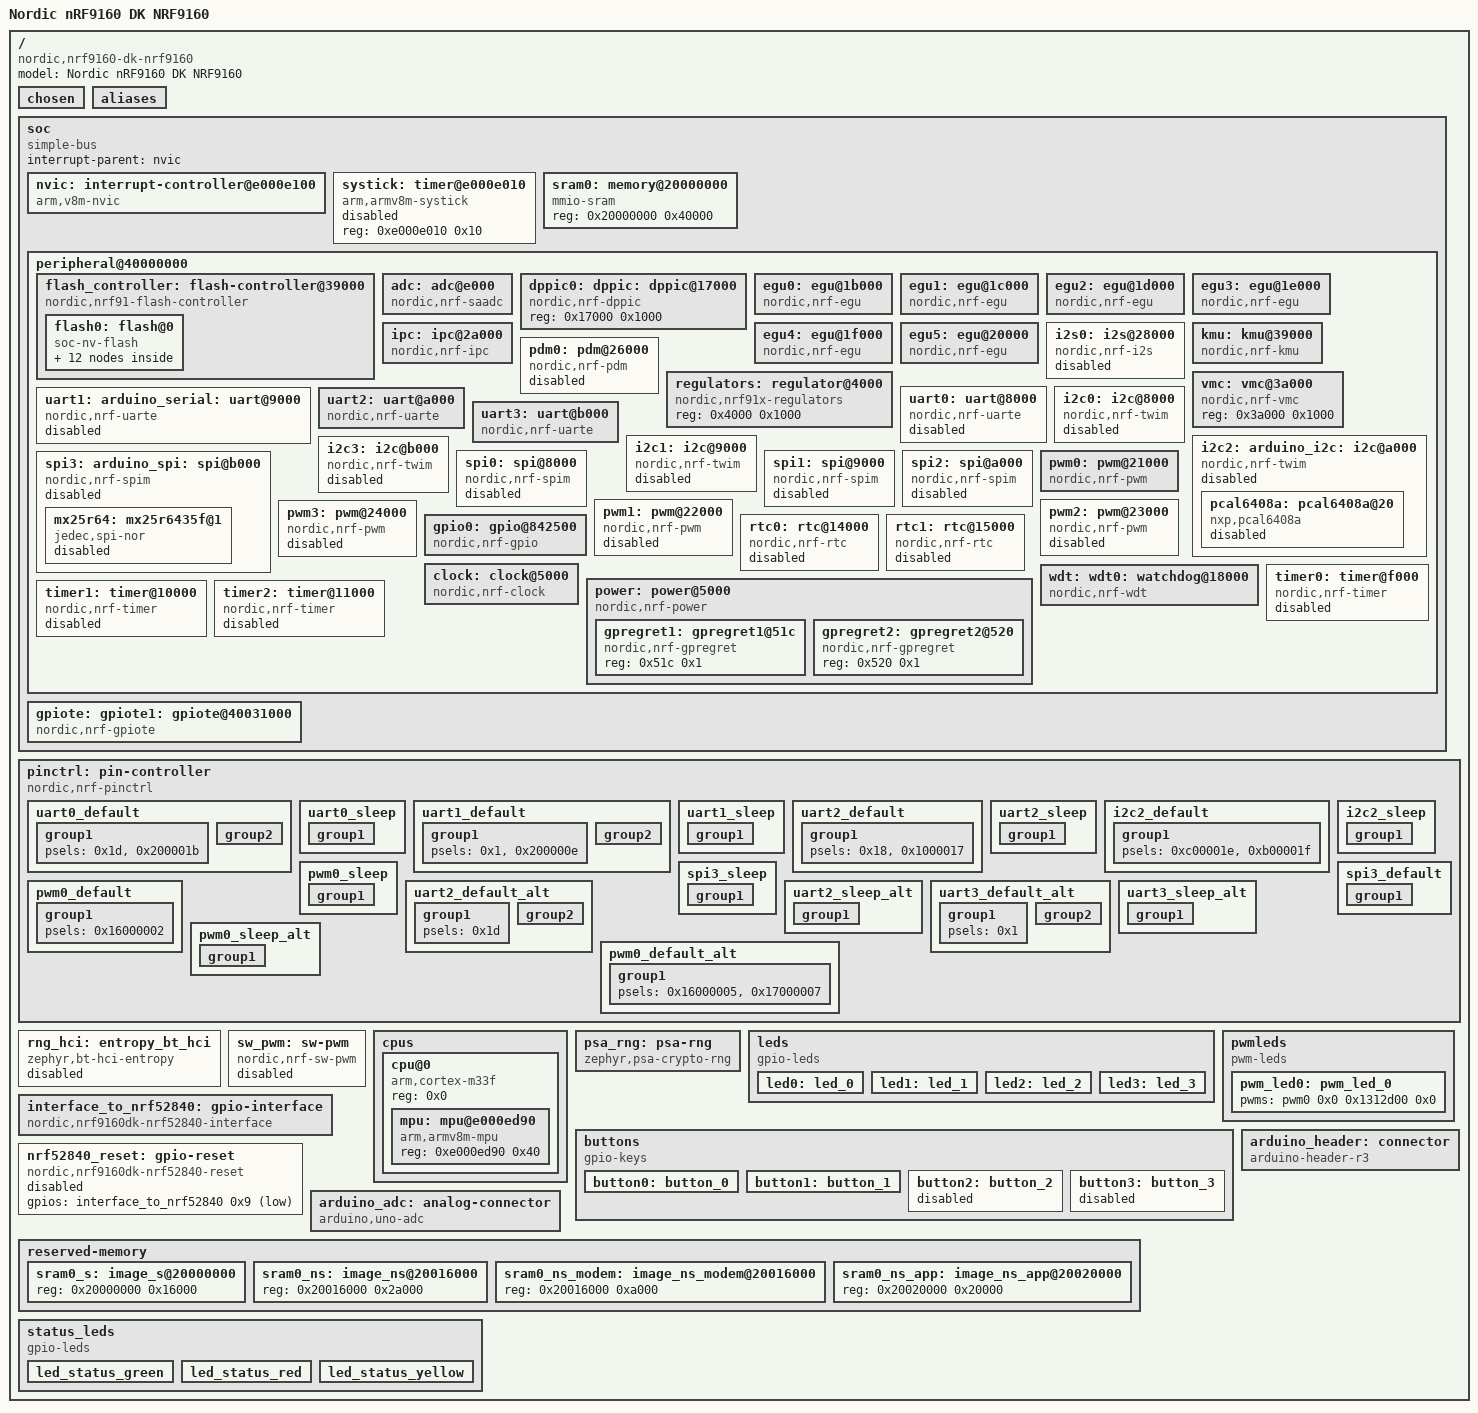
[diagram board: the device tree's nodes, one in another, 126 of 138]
/dts-v1/;

/* node '/' defined in zephyr\dts\common\skeleton.dtsi:9 */
/ {
	#address-cells = < 0x1 >;                 /* in zephyr\dts\common\skeleton.dtsi:10 */
	#size-cells = < 0x1 >;                    /* in zephyr\dts\common\skeleton.dtsi:11 */
	model = "Nordic nRF9160 DK NRF9160";      /* in zephyr\boards\nordic\nrf9160dk\nrf9160dk_nrf9160_common.dtsi:11 */
	compatible = "nordic,nrf9160-dk-nrf9160"; /* in zephyr\boards\nordic\nrf9160dk\nrf9160dk_nrf9160_common.dtsi:12 */

	/* node '/chosen' defined in zephyr\dts\common\skeleton.dtsi:12 */
	chosen {
		zephyr,entropy = &psa_rng;                   /* in zephyr\dts\arm\nordic\nrf91ns.dtsi:31 */
		zephyr,flash-controller = &flash_controller; /* in zephyr\dts\arm\nordic\nrf91ns.dtsi:32 */
		zephyr,console = &uart0;                     /* in zephyr\boards\nordic\nrf9160dk\nrf9160dk_nrf9160_common.dtsi:15 */
		zephyr,shell-uart = &uart0;                  /* in zephyr\boards\nordic\nrf9160dk\nrf9160dk_nrf9160_common.dtsi:16 */
		zephyr,uart-mcumgr = &uart0;                 /* in zephyr\boards\nordic\nrf9160dk\nrf9160dk_nrf9160_common.dtsi:17 */
		zephyr,flash = &flash0;                      /* in zephyr\boards\nordic\nrf9160dk\nrf9160dk_nrf9160_ns.dts:13 */
		zephyr,sram = &sram0_ns_app;                 /* in zephyr\boards\nordic\nrf9160dk\nrf9160dk_nrf9160_ns.dts:14 */
		zephyr,code-partition = &slot0_ns_partition; /* in zephyr\boards\nordic\nrf9160dk\nrf9160dk_nrf9160_ns.dts:15 */
	};

	/* node '/aliases' defined in zephyr\dts\common\skeleton.dtsi:13 */
	aliases {
		led0 = &led0;                           /* in zephyr\boards\nordic\nrf9160dk\nrf9160dk_nrf9160_common.dtsi:155 */
		led1 = &led1;                           /* in zephyr\boards\nordic\nrf9160dk\nrf9160dk_nrf9160_common.dtsi:156 */
		led2 = &led2;                           /* in zephyr\boards\nordic\nrf9160dk\nrf9160dk_nrf9160_common.dtsi:157 */
		led3 = &led3;                           /* in zephyr\boards\nordic\nrf9160dk\nrf9160dk_nrf9160_common.dtsi:158 */
		pwm-led0 = &pwm_led0;                   /* in zephyr\boards\nordic\nrf9160dk\nrf9160dk_nrf9160_common.dtsi:159 */
		sw0 = &button0;                         /* in zephyr\boards\nordic\nrf9160dk\nrf9160dk_nrf9160_common.dtsi:160 */
		sw1 = &button1;                         /* in zephyr\boards\nordic\nrf9160dk\nrf9160dk_nrf9160_common.dtsi:161 */
		sw2 = &button2;                         /* in zephyr\boards\nordic\nrf9160dk\nrf9160dk_nrf9160_common.dtsi:162 */
		sw3 = &button3;                         /* in zephyr\boards\nordic\nrf9160dk\nrf9160dk_nrf9160_common.dtsi:163 */
		mcuboot-button0 = &button0;             /* in zephyr\boards\nordic\nrf9160dk\nrf9160dk_nrf9160_common.dtsi:164 */
		mcuboot-led0 = &led0;                   /* in zephyr\boards\nordic\nrf9160dk\nrf9160dk_nrf9160_common.dtsi:165 */
		watchdog0 = &wdt0;                      /* in zephyr\boards\nordic\nrf9160dk\nrf9160dk_nrf9160_common.dtsi:166 */
		gps-uart = &uart2;                      /* in ..\firmware_dev\app.overlay:25 */
		esp-uart = &uart3;                      /* in ..\firmware_dev\app.overlay:26 */
		status-led = &led0;                     /* in ..\firmware_dev\app.overlay:28 */
		status-led-green = &led_status_green;   /* in ..\firmware_dev\app.overlay:30 */
		status-led-red = &led_status_red;       /* in ..\firmware_dev\app.overlay:31 */
		status-led-yellow = &led_status_yellow; /* in ..\firmware_dev\app.overlay:32 */
	};

	/* node '/soc' defined in zephyr\dts\arm\armv8-m.dtsi:6 */
	soc {
		#address-cells = < 0x1 >;     /* in zephyr\dts\arm\armv8-m.dtsi:7 */
		#size-cells = < 0x1 >;        /* in zephyr\dts\arm\armv8-m.dtsi:8 */
		interrupt-parent = < &nvic >; /* in zephyr\dts\arm\armv8-m.dtsi:10 */
		ranges;                       /* in zephyr\dts\arm\armv8-m.dtsi:11 */
		compatible = "simple-bus";    /* in zephyr\dts\arm\nordic\nrf9160ns_sica.dtsi:20 */

		/* node '/soc/interrupt-controller@e000e100' defined in zephyr\dts\arm\armv8-m.dtsi:13 */
		nvic: interrupt-controller@e000e100 {
			#address-cells = < 0x1 >;            /* in zephyr\dts\arm\armv8-m.dtsi:14 */
			compatible = "arm,v8m-nvic";         /* in zephyr\dts\arm\armv8-m.dtsi:15 */
			reg = < 0xe000e100 0xc00 >;          /* in zephyr\dts\arm\armv8-m.dtsi:16 */
			interrupt-controller;                /* in zephyr\dts\arm\armv8-m.dtsi:17 */
			#interrupt-cells = < 0x2 >;          /* in zephyr\dts\arm\armv8-m.dtsi:18 */
			arm,num-irq-priority-bits = < 0x3 >; /* in zephyr\dts\arm\nordic\nrf91ns.dtsi:70 */
			phandle = < 0x1 >;                   /* in zephyr\dts\arm\armv8-m.dtsi:10 */
		};

		/* node '/soc/timer@e000e010' defined in zephyr\dts\arm\armv8-m.dtsi:21 */
		systick: timer@e000e010 {
			compatible = "arm,armv8m-systick"; /* in zephyr\dts\arm\armv8-m.dtsi:22 */
			reg = < 0xe000e010 0x10 >;         /* in zephyr\dts\arm\armv8-m.dtsi:23 */
			status = "disabled";               /* in zephyr\dts\arm\nordic\nrf91ns.dtsi:75 */
		};

		/* node '/soc/memory@20000000' defined in zephyr\dts\arm\nordic\nrf91ns.dtsi:36 */
		sram0: memory@20000000 {
			compatible = "mmio-sram";     /* in zephyr\dts\arm\nordic\nrf91ns.dtsi:37 */
			reg = < 0x20000000 0x40000 >; /* in zephyr\dts\arm\nordic\nrf9160ns_sica.dtsi:15 */
		};

		/* node '/soc/peripheral@40000000' defined in zephyr\dts\arm\nordic\nrf91ns.dtsi:40 */
		peripheral@40000000 {
			#address-cells = < 0x1 >;               /* in zephyr\dts\arm\nordic\nrf91ns.dtsi:41 */
			#size-cells = < 0x1 >;                  /* in zephyr\dts\arm\nordic\nrf91ns.dtsi:42 */
			ranges = < 0x0 0x40000000 0x10000000 >; /* in zephyr\dts\arm\nordic\nrf91ns.dtsi:43 */

			/* node '/soc/peripheral@40000000/flash-controller@39000' defined in zephyr\dts\arm\nordic\nrf91_peripherals.dtsi:7 */
			flash_controller: flash-controller@39000 {
				compatible = "nordic,nrf91-flash-controller"; /* in zephyr\dts\arm\nordic\nrf91_peripherals.dtsi:8 */
				reg = < 0x39000 0x1000 >;                     /* in zephyr\dts\arm\nordic\nrf91_peripherals.dtsi:9 */
				partial-erase;                                /* in zephyr\dts\arm\nordic\nrf91_peripherals.dtsi:10 */
				#address-cells = < 0x1 >;                     /* in zephyr\dts\arm\nordic\nrf91_peripherals.dtsi:12 */
				#size-cells = < 0x1 >;                        /* in zephyr\dts\arm\nordic\nrf91_peripherals.dtsi:13 */

				/* node '/soc/peripheral@40000000/flash-controller@39000/flash@0' defined in zephyr\dts\arm\nordic\nrf91_peripherals.dtsi:15 */
				flash0: flash@0 {
					compatible = "soc-nv-flash";   /* in zephyr\dts\arm\nordic\nrf91_peripherals.dtsi:16 */
					erase-block-size = < 0x1000 >; /* in zephyr\dts\arm\nordic\nrf91_peripherals.dtsi:17 */
					write-block-size = < 0x4 >;    /* in zephyr\dts\arm\nordic\nrf91_peripherals.dtsi:18 */
					reg = < 0x0 0x100000 >;        /* in zephyr\dts\arm\nordic\nrf9160ns_sica.dtsi:11 */

					/* node '/soc/peripheral@40000000/flash-controller@39000/flash@0/partitions' defined in zephyr\dts\vendor\nordic\nrf91xx_partition.dtsi:27 */
					partitions {
						compatible = "fixed-partitions"; /* in zephyr\dts\vendor\nordic\nrf91xx_partition.dtsi:28 */
						#address-cells = < 0x1 >;        /* in zephyr\dts\vendor\nordic\nrf91xx_partition.dtsi:29 */
						#size-cells = < 0x1 >;           /* in zephyr\dts\vendor\nordic\nrf91xx_partition.dtsi:30 */

						/* node '/soc/peripheral@40000000/flash-controller@39000/flash@0/partitions/partition@0' defined in zephyr\dts\vendor\nordic\nrf91xx_partition.dtsi:32 */
						boot_partition: partition@0 {
							label = "mcuboot";     /* in zephyr\dts\vendor\nordic\nrf91xx_partition.dtsi:33 */
							reg = < 0x0 0x10000 >; /* in zephyr\dts\vendor\nordic\nrf91xx_partition.dtsi:34 */
						};

						/* node '/soc/peripheral@40000000/flash-controller@39000/flash@0/partitions/partition@10000' defined in zephyr\dts\vendor\nordic\nrf91xx_partition.dtsi:37 */
						slot0_partition: partition@10000 {
							compatible = "fixed-subpartitions"; /* in zephyr\dts\vendor\nordic\nrf91xx_partition.dtsi:38 */
							label = "image-0";                  /* in zephyr\dts\vendor\nordic\nrf91xx_partition.dtsi:39 */
							reg = < 0x10000 0x70000 >;          /* in zephyr\dts\vendor\nordic\nrf91xx_partition.dtsi:40 */
							ranges = < 0x0 0x10000 0x70000 >;   /* in zephyr\dts\vendor\nordic\nrf91xx_partition.dtsi:41 */
							#address-cells = < 0x1 >;           /* in zephyr\dts\vendor\nordic\nrf91xx_partition.dtsi:42 */
							#size-cells = < 0x1 >;              /* in zephyr\dts\vendor\nordic\nrf91xx_partition.dtsi:43 */

							/* node '/soc/peripheral@40000000/flash-controller@39000/flash@0/partitions/partition@10000/partition@0' defined in zephyr\dts\vendor\nordic\nrf91xx_partition.dtsi:45 */
							slot0_s_partition: partition@0 {
								label = "image-0-secure"; /* in zephyr\dts\vendor\nordic\nrf91xx_partition.dtsi:46 */
								reg = < 0x0 0x40000 >;    /* in zephyr\dts\vendor\nordic\nrf91xx_partition.dtsi:47 */
							};

							/* node '/soc/peripheral@40000000/flash-controller@39000/flash@0/partitions/partition@10000/partition@40000' defined in zephyr\dts\vendor\nordic\nrf91xx_partition.dtsi:50 */
							slot0_ns_partition: partition@40000 {
								label = "image-0-nonsecure"; /* in zephyr\dts\vendor\nordic\nrf91xx_partition.dtsi:51 */
								reg = < 0x40000 0x30000 >;   /* in zephyr\dts\vendor\nordic\nrf91xx_partition.dtsi:52 */
							};
						};

						/* node '/soc/peripheral@40000000/flash-controller@39000/flash@0/partitions/partition@80000' defined in zephyr\dts\vendor\nordic\nrf91xx_partition.dtsi:56 */
						slot1_partition: partition@80000 {
							compatible = "fixed-subpartitions"; /* in zephyr\dts\vendor\nordic\nrf91xx_partition.dtsi:57 */
							label = "image-1";                  /* in zephyr\dts\vendor\nordic\nrf91xx_partition.dtsi:58 */
							reg = < 0x80000 0x70000 >;          /* in zephyr\dts\vendor\nordic\nrf91xx_partition.dtsi:59 */
							ranges = < 0x0 0x80000 0x70000 >;   /* in zephyr\dts\vendor\nordic\nrf91xx_partition.dtsi:60 */
							#address-cells = < 0x1 >;           /* in zephyr\dts\vendor\nordic\nrf91xx_partition.dtsi:61 */
							#size-cells = < 0x1 >;              /* in zephyr\dts\vendor\nordic\nrf91xx_partition.dtsi:62 */

							/* node '/soc/peripheral@40000000/flash-controller@39000/flash@0/partitions/partition@80000/partition@0' defined in zephyr\dts\vendor\nordic\nrf91xx_partition.dtsi:64 */
							slot1_s_partition: partition@0 {
								label = "image-1-secure"; /* in zephyr\dts\vendor\nordic\nrf91xx_partition.dtsi:65 */
								reg = < 0x0 0x40000 >;    /* in zephyr\dts\vendor\nordic\nrf91xx_partition.dtsi:66 */
							};

							/* node '/soc/peripheral@40000000/flash-controller@39000/flash@0/partitions/partition@80000/partition@40000' defined in zephyr\dts\vendor\nordic\nrf91xx_partition.dtsi:69 */
							slot1_ns_partition: partition@40000 {
								label = "image-1-nonsecure"; /* in zephyr\dts\vendor\nordic\nrf91xx_partition.dtsi:70 */
								reg = < 0x40000 0x30000 >;   /* in zephyr\dts\vendor\nordic\nrf91xx_partition.dtsi:71 */
							};
						};

						/* node '/soc/peripheral@40000000/flash-controller@39000/flash@0/partitions/partition@f0000' defined in zephyr\dts\vendor\nordic\nrf91xx_partition.dtsi:75 */
						tfm_ps_partition: partition@f0000 {
							label = "tfm-ps";         /* in zephyr\dts\vendor\nordic\nrf91xx_partition.dtsi:76 */
							reg = < 0xf0000 0x4000 >; /* in zephyr\dts\vendor\nordic\nrf91xx_partition.dtsi:77 */
						};

						/* node '/soc/peripheral@40000000/flash-controller@39000/flash@0/partitions/partition@f4000' defined in zephyr\dts\vendor\nordic\nrf91xx_partition.dtsi:80 */
						tfm_its_partition: partition@f4000 {
							label = "tfm-its";        /* in zephyr\dts\vendor\nordic\nrf91xx_partition.dtsi:81 */
							reg = < 0xf4000 0x2000 >; /* in zephyr\dts\vendor\nordic\nrf91xx_partition.dtsi:82 */
						};

						/* node '/soc/peripheral@40000000/flash-controller@39000/flash@0/partitions/partition@f6000' defined in zephyr\dts\vendor\nordic\nrf91xx_partition.dtsi:85 */
						tfm_otp_partition: partition@f6000 {
							label = "tfm-otp";        /* in zephyr\dts\vendor\nordic\nrf91xx_partition.dtsi:86 */
							reg = < 0xf6000 0x2000 >; /* in zephyr\dts\vendor\nordic\nrf91xx_partition.dtsi:87 */
						};

						/* node '/soc/peripheral@40000000/flash-controller@39000/flash@0/partitions/partition@f8000' defined in zephyr\dts\vendor\nordic\nrf91xx_partition.dtsi:90 */
						storage_partition: partition@f8000 {
							label = "storage";        /* in zephyr\dts\vendor\nordic\nrf91xx_partition.dtsi:91 */
							reg = < 0xf8000 0x8000 >; /* in zephyr\dts\vendor\nordic\nrf91xx_partition.dtsi:92 */
						};
					};
				};
			};

			/* node '/soc/peripheral@40000000/adc@e000' defined in zephyr\dts\arm\nordic\nrf91_peripherals.dtsi:22 */
			adc: adc@e000 {
				compatible = "nordic,nrf-saadc"; /* in zephyr\dts\arm\nordic\nrf91_peripherals.dtsi:23 */
				reg = < 0xe000 0x1000 >;         /* in zephyr\dts\arm\nordic\nrf91_peripherals.dtsi:24 */
				interrupts = < 0xe 0x1 >;        /* in zephyr\dts\arm\nordic\nrf91_peripherals.dtsi:25 */
				#io-channel-cells = < 0x1 >;     /* in zephyr\dts\arm\nordic\nrf91_peripherals.dtsi:27 */
				zephyr,pm-device-runtime-auto;   /* in zephyr\dts\arm\nordic\nrf91_peripherals.dtsi:28 */
				status = "okay";                 /* in zephyr\boards\nordic\nrf9160dk\nrf9160dk_nrf9160_common.dtsi:171 */
				phandle = < 0x16 >;              /* in zephyr\boards\nordic\nrf9160dk\nrf9160dk_nrf9160_common.dtsi:145 */
			};

			/* node '/soc/peripheral@40000000/dppic@17000' defined in zephyr\dts\arm\nordic\nrf91_peripherals.dtsi:31 */
			dppic0: dppic: dppic@17000 {
				compatible = "nordic,nrf-dppic"; /* in zephyr\dts\arm\nordic\nrf91_peripherals.dtsi:32 */
				reg = < 0x17000 0x1000 >;        /* in zephyr\dts\arm\nordic\nrf91_peripherals.dtsi:33 */
				status = "okay";                 /* in zephyr\dts\arm\nordic\nrf91_peripherals.dtsi:34 */
			};

			/* node '/soc/peripheral@40000000/egu@1b000' defined in zephyr\dts\arm\nordic\nrf91_peripherals.dtsi:37 */
			egu0: egu@1b000 {
				compatible = "nordic,nrf-egu"; /* in zephyr\dts\arm\nordic\nrf91_peripherals.dtsi:38 */
				reg = < 0x1b000 0x1000 >;      /* in zephyr\dts\arm\nordic\nrf91_peripherals.dtsi:39 */
				interrupts = < 0x1b 0x1 >;     /* in zephyr\dts\arm\nordic\nrf91_peripherals.dtsi:40 */
				status = "okay";               /* in zephyr\dts\arm\nordic\nrf91_peripherals.dtsi:41 */
			};

			/* node '/soc/peripheral@40000000/egu@1c000' defined in zephyr\dts\arm\nordic\nrf91_peripherals.dtsi:44 */
			egu1: egu@1c000 {
				compatible = "nordic,nrf-egu"; /* in zephyr\dts\arm\nordic\nrf91_peripherals.dtsi:45 */
				reg = < 0x1c000 0x1000 >;      /* in zephyr\dts\arm\nordic\nrf91_peripherals.dtsi:46 */
				interrupts = < 0x1c 0x1 >;     /* in zephyr\dts\arm\nordic\nrf91_peripherals.dtsi:47 */
				status = "okay";               /* in zephyr\dts\arm\nordic\nrf91_peripherals.dtsi:48 */
			};

			/* node '/soc/peripheral@40000000/egu@1d000' defined in zephyr\dts\arm\nordic\nrf91_peripherals.dtsi:51 */
			egu2: egu@1d000 {
				compatible = "nordic,nrf-egu"; /* in zephyr\dts\arm\nordic\nrf91_peripherals.dtsi:52 */
				reg = < 0x1d000 0x1000 >;      /* in zephyr\dts\arm\nordic\nrf91_peripherals.dtsi:53 */
				interrupts = < 0x1d 0x1 >;     /* in zephyr\dts\arm\nordic\nrf91_peripherals.dtsi:54 */
				status = "okay";               /* in zephyr\dts\arm\nordic\nrf91_peripherals.dtsi:55 */
			};

			/* node '/soc/peripheral@40000000/egu@1e000' defined in zephyr\dts\arm\nordic\nrf91_peripherals.dtsi:58 */
			egu3: egu@1e000 {
				compatible = "nordic,nrf-egu"; /* in zephyr\dts\arm\nordic\nrf91_peripherals.dtsi:59 */
				reg = < 0x1e000 0x1000 >;      /* in zephyr\dts\arm\nordic\nrf91_peripherals.dtsi:60 */
				interrupts = < 0x1e 0x1 >;     /* in zephyr\dts\arm\nordic\nrf91_peripherals.dtsi:61 */
				status = "okay";               /* in zephyr\dts\arm\nordic\nrf91_peripherals.dtsi:62 */
			};

			/* node '/soc/peripheral@40000000/egu@1f000' defined in zephyr\dts\arm\nordic\nrf91_peripherals.dtsi:65 */
			egu4: egu@1f000 {
				compatible = "nordic,nrf-egu"; /* in zephyr\dts\arm\nordic\nrf91_peripherals.dtsi:66 */
				reg = < 0x1f000 0x1000 >;      /* in zephyr\dts\arm\nordic\nrf91_peripherals.dtsi:67 */
				interrupts = < 0x1f 0x1 >;     /* in zephyr\dts\arm\nordic\nrf91_peripherals.dtsi:68 */
				status = "okay";               /* in zephyr\dts\arm\nordic\nrf91_peripherals.dtsi:69 */
			};

			/* node '/soc/peripheral@40000000/egu@20000' defined in zephyr\dts\arm\nordic\nrf91_peripherals.dtsi:72 */
			egu5: egu@20000 {
				compatible = "nordic,nrf-egu"; /* in zephyr\dts\arm\nordic\nrf91_peripherals.dtsi:73 */
				reg = < 0x20000 0x1000 >;      /* in zephyr\dts\arm\nordic\nrf91_peripherals.dtsi:74 */
				interrupts = < 0x20 0x1 >;     /* in zephyr\dts\arm\nordic\nrf91_peripherals.dtsi:75 */
				status = "okay";               /* in zephyr\dts\arm\nordic\nrf91_peripherals.dtsi:76 */
			};

			/* node '/soc/peripheral@40000000/ipc@2a000' defined in zephyr\dts\arm\nordic\nrf91_peripherals.dtsi:79 */
			ipc: ipc@2a000 {
				compatible = "nordic,nrf-ipc"; /* in zephyr\dts\arm\nordic\nrf91_peripherals.dtsi:80 */
				reg = < 0x2a000 0x1000 >;      /* in zephyr\dts\arm\nordic\nrf91_peripherals.dtsi:81 */
				interrupts = < 0x2a 0x1 >;     /* in zephyr\dts\arm\nordic\nrf91_peripherals.dtsi:82 */
				status = "okay";               /* in zephyr\dts\arm\nordic\nrf91_peripherals.dtsi:83 */
			};

			/* node '/soc/peripheral@40000000/i2s@28000' defined in zephyr\dts\arm\nordic\nrf91_peripherals.dtsi:86 */
			i2s0: i2s@28000 {
				compatible = "nordic,nrf-i2s"; /* in zephyr\dts\arm\nordic\nrf91_peripherals.dtsi:87 */
				#address-cells = < 0x1 >;      /* in zephyr\dts\arm\nordic\nrf91_peripherals.dtsi:88 */
				#size-cells = < 0x0 >;         /* in zephyr\dts\arm\nordic\nrf91_peripherals.dtsi:89 */
				reg = < 0x28000 0x1000 >;      /* in zephyr\dts\arm\nordic\nrf91_peripherals.dtsi:90 */
				interrupts = < 0x28 0x1 >;     /* in zephyr\dts\arm\nordic\nrf91_peripherals.dtsi:91 */
				status = "disabled";           /* in zephyr\dts\arm\nordic\nrf91_peripherals.dtsi:92 */
			};

			/* node '/soc/peripheral@40000000/kmu@39000' defined in zephyr\dts\arm\nordic\nrf91_peripherals.dtsi:95 */
			kmu: kmu@39000 {
				compatible = "nordic,nrf-kmu"; /* in zephyr\dts\arm\nordic\nrf91_peripherals.dtsi:96 */
				reg = < 0x39000 0x1000 >;      /* in zephyr\dts\arm\nordic\nrf91_peripherals.dtsi:97 */
				interrupts = < 0x39 0x1 >;     /* in zephyr\dts\arm\nordic\nrf91_peripherals.dtsi:98 */
				status = "okay";               /* in zephyr\dts\arm\nordic\nrf91_peripherals.dtsi:99 */
			};

			/* node '/soc/peripheral@40000000/pdm@26000' defined in zephyr\dts\arm\nordic\nrf91_peripherals.dtsi:102 */
			pdm0: pdm@26000 {
				compatible = "nordic,nrf-pdm"; /* in zephyr\dts\arm\nordic\nrf91_peripherals.dtsi:103 */
				reg = < 0x26000 0x1000 >;      /* in zephyr\dts\arm\nordic\nrf91_peripherals.dtsi:104 */
				interrupts = < 0x26 0x1 >;     /* in zephyr\dts\arm\nordic\nrf91_peripherals.dtsi:105 */
				status = "disabled";           /* in zephyr\dts\arm\nordic\nrf91_peripherals.dtsi:106 */
			};

			/* node '/soc/peripheral@40000000/regulator@4000' defined in zephyr\dts\arm\nordic\nrf91_peripherals.dtsi:109 */
			regulators: regulator@4000 {
				compatible = "nordic,nrf91x-regulators"; /* in zephyr\dts\arm\nordic\nrf91_peripherals.dtsi:110 */
				reg = < 0x4000 0x1000 >;                 /* in zephyr\dts\arm\nordic\nrf91_peripherals.dtsi:111 */
				status = "okay";                         /* in zephyr\dts\arm\nordic\nrf91_peripherals.dtsi:112 */
			};

			/* node '/soc/peripheral@40000000/vmc@3a000' defined in zephyr\dts\arm\nordic\nrf91_peripherals.dtsi:115 */
			vmc: vmc@3a000 {
				compatible = "nordic,nrf-vmc"; /* in zephyr\dts\arm\nordic\nrf91_peripherals.dtsi:116 */
				reg = < 0x3a000 0x1000 >;      /* in zephyr\dts\arm\nordic\nrf91_peripherals.dtsi:117 */
				status = "okay";               /* in zephyr\dts\arm\nordic\nrf91_peripherals.dtsi:118 */
			};

			/* node '/soc/peripheral@40000000/uart@8000' defined in zephyr\dts\arm\nordic\nrf91_peripherals.dtsi:121 */
			uart0: uart@8000 {
				compatible = "nordic,nrf-uarte"; /* in zephyr\dts\arm\nordic\nrf91_peripherals.dtsi:122 */
				reg = < 0x8000 0x1000 >;         /* in zephyr\dts\arm\nordic\nrf91_peripherals.dtsi:123 */
				interrupts = < 0x8 0x1 >;        /* in zephyr\dts\arm\nordic\nrf91_peripherals.dtsi:124 */
				current-speed = < 0x1c200 >;     /* in zephyr\boards\nordic\nrf9160dk\nrf9160dk_nrf9160_common.dtsi:184 */
				pinctrl-0 = < &uart0_default >;  /* in zephyr\boards\nordic\nrf9160dk\nrf9160dk_nrf9160_common.dtsi:185 */
				pinctrl-1 = < &uart0_sleep >;    /* in zephyr\boards\nordic\nrf9160dk\nrf9160dk_nrf9160_common.dtsi:186 */
				pinctrl-names = "default",
				                "sleep";         /* in zephyr\boards\nordic\nrf9160dk\nrf9160dk_nrf9160_common.dtsi:187 */
				status = "disabled";             /* in ..\firmware_dev\app.overlay:133 */
			};

			/* node '/soc/peripheral@40000000/uart@9000' defined in zephyr\dts\arm\nordic\nrf91_peripherals.dtsi:128 */
			uart1: arduino_serial: uart@9000 {
				compatible = "nordic,nrf-uarte"; /* in zephyr\dts\arm\nordic\nrf91_peripherals.dtsi:129 */
				reg = < 0x9000 0x1000 >;         /* in zephyr\dts\arm\nordic\nrf91_peripherals.dtsi:130 */
				interrupts = < 0x9 0x1 >;        /* in zephyr\dts\arm\nordic\nrf91_peripherals.dtsi:131 */
				current-speed = < 0x1c200 >;     /* in zephyr\boards\nordic\nrf9160dk\nrf9160dk_nrf9160_common.dtsi:192 */
				pinctrl-0 = < &uart1_default >;  /* in zephyr\boards\nordic\nrf9160dk\nrf9160dk_nrf9160_common.dtsi:193 */
				pinctrl-1 = < &uart1_sleep >;    /* in zephyr\boards\nordic\nrf9160dk\nrf9160dk_nrf9160_common.dtsi:194 */
				pinctrl-names = "default",
				                "sleep";         /* in zephyr\boards\nordic\nrf9160dk\nrf9160dk_nrf9160_common.dtsi:195 */
				status = "disabled";             /* in zephyr\boards\nordic\nrf9160dk\nrf9160dk_nrf9160_ns.dts:21 */
			};

			/* node '/soc/peripheral@40000000/uart@a000' defined in zephyr\dts\arm\nordic\nrf91_peripherals.dtsi:135 */
			uart2: uart@a000 {
				compatible = "nordic,nrf-uarte";    /* in zephyr\dts\arm\nordic\nrf91_peripherals.dtsi:136 */
				reg = < 0xa000 0x1000 >;            /* in zephyr\dts\arm\nordic\nrf91_peripherals.dtsi:137 */
				interrupts = < 0xa 0x1 >;           /* in zephyr\dts\arm\nordic\nrf91_peripherals.dtsi:138 */
				status = "okay";                    /* in ..\firmware_dev\app.overlay:163 */
				current-speed = < 0x9600 >;         /* in ..\firmware_dev\app.overlay:164 */
				pinctrl-0 = < &uart2_default_alt >; /* in ..\firmware_dev\app.overlay:165 */
				pinctrl-1 = < &uart2_sleep_alt >;   /* in ..\firmware_dev\app.overlay:166 */
				pinctrl-names = "default",
				                "sleep";            /* in ..\firmware_dev\app.overlay:167 */
			};

			/* node '/soc/peripheral@40000000/uart@b000' defined in zephyr\dts\arm\nordic\nrf91_peripherals.dtsi:142 */
			uart3: uart@b000 {
				compatible = "nordic,nrf-uarte";    /* in zephyr\dts\arm\nordic\nrf91_peripherals.dtsi:143 */
				reg = < 0xb000 0x1000 >;            /* in zephyr\dts\arm\nordic\nrf91_peripherals.dtsi:144 */
				interrupts = < 0xb 0x1 >;           /* in zephyr\dts\arm\nordic\nrf91_peripherals.dtsi:145 */
				status = "okay";                    /* in ..\firmware_dev\app.overlay:147 */
				current-speed = < 0x1c200 >;        /* in ..\firmware_dev\app.overlay:148 */
				pinctrl-0 = < &uart3_default_alt >; /* in ..\firmware_dev\app.overlay:149 */
				pinctrl-1 = < &uart3_sleep_alt >;   /* in ..\firmware_dev\app.overlay:150 */
				pinctrl-names = "default",
				                "sleep";            /* in ..\firmware_dev\app.overlay:151 */
			};

			/* node '/soc/peripheral@40000000/i2c@8000' defined in zephyr\dts\arm\nordic\nrf91_peripherals.dtsi:149 */
			i2c0: i2c@8000 {
				compatible = "nordic,nrf-twim"; /* in zephyr\dts\arm\nordic\nrf91_peripherals.dtsi:155 */
				#address-cells = < 0x1 >;       /* in zephyr\dts\arm\nordic\nrf91_peripherals.dtsi:156 */
				#size-cells = < 0x0 >;          /* in zephyr\dts\arm\nordic\nrf91_peripherals.dtsi:157 */
				reg = < 0x8000 0x1000 >;        /* in zephyr\dts\arm\nordic\nrf91_peripherals.dtsi:158 */
				interrupts = < 0x8 0x1 >;       /* in zephyr\dts\arm\nordic\nrf91_peripherals.dtsi:159 */
				easydma-maxcnt-bits = < 0xd >;  /* in zephyr\dts\arm\nordic\nrf91_peripherals.dtsi:160 */
				status = "disabled";            /* in zephyr\dts\arm\nordic\nrf91_peripherals.dtsi:161 */
				zephyr,pm-device-runtime-auto;  /* in zephyr\dts\arm\nordic\nrf91_peripherals.dtsi:162 */
			};

			/* node '/soc/peripheral@40000000/i2c@9000' defined in zephyr\dts\arm\nordic\nrf91_peripherals.dtsi:165 */
			i2c1: i2c@9000 {
				compatible = "nordic,nrf-twim"; /* in zephyr\dts\arm\nordic\nrf91_peripherals.dtsi:171 */
				#address-cells = < 0x1 >;       /* in zephyr\dts\arm\nordic\nrf91_peripherals.dtsi:172 */
				#size-cells = < 0x0 >;          /* in zephyr\dts\arm\nordic\nrf91_peripherals.dtsi:173 */
				reg = < 0x9000 0x1000 >;        /* in zephyr\dts\arm\nordic\nrf91_peripherals.dtsi:174 */
				interrupts = < 0x9 0x1 >;       /* in zephyr\dts\arm\nordic\nrf91_peripherals.dtsi:175 */
				easydma-maxcnt-bits = < 0xd >;  /* in zephyr\dts\arm\nordic\nrf91_peripherals.dtsi:176 */
				status = "disabled";            /* in zephyr\dts\arm\nordic\nrf91_peripherals.dtsi:177 */
				zephyr,pm-device-runtime-auto;  /* in zephyr\dts\arm\nordic\nrf91_peripherals.dtsi:178 */
			};

			/* node '/soc/peripheral@40000000/i2c@a000' defined in zephyr\dts\arm\nordic\nrf91_peripherals.dtsi:181 */
			i2c2: arduino_i2c: i2c@a000 {
				#address-cells = < 0x1 >;       /* in zephyr\dts\arm\nordic\nrf91_peripherals.dtsi:188 */
				#size-cells = < 0x0 >;          /* in zephyr\dts\arm\nordic\nrf91_peripherals.dtsi:189 */
				reg = < 0xa000 0x1000 >;        /* in zephyr\dts\arm\nordic\nrf91_peripherals.dtsi:190 */
				interrupts = < 0xa 0x1 >;       /* in zephyr\dts\arm\nordic\nrf91_peripherals.dtsi:191 */
				easydma-maxcnt-bits = < 0xd >;  /* in zephyr\dts\arm\nordic\nrf91_peripherals.dtsi:192 */
				zephyr,pm-device-runtime-auto;  /* in zephyr\dts\arm\nordic\nrf91_peripherals.dtsi:194 */
				compatible = "nordic,nrf-twim"; /* in zephyr\boards\nordic\nrf9160dk\nrf9160dk_nrf9160_common.dtsi:205 */
				pinctrl-0 = < &i2c2_default >;  /* in zephyr\boards\nordic\nrf9160dk\nrf9160dk_nrf9160_common.dtsi:207 */
				pinctrl-1 = < &i2c2_sleep >;    /* in zephyr\boards\nordic\nrf9160dk\nrf9160dk_nrf9160_common.dtsi:208 */
				pinctrl-names = "default",
				                "sleep";        /* in zephyr\boards\nordic\nrf9160dk\nrf9160dk_nrf9160_common.dtsi:209 */
				clock-frequency = < 0x61a80 >;  /* in zephyr\boards\nordic\nrf9160dk\nrf9160dk_nrf9160_common_0_14_0.dtsi:26 */
				status = "disabled";            /* in ..\firmware_dev\app.overlay:138 */

				/* node '/soc/peripheral@40000000/i2c@a000/pcal6408a@20' defined in zephyr\boards\nordic\nrf9160dk\nrf9160dk_nrf9160_common_0_14_0.dtsi:28 */
				pcal6408a: pcal6408a@20 {
					compatible = "nxp,pcal6408a";    /* in zephyr\boards\nordic\nrf9160dk\nrf9160dk_nrf9160_common_0_14_0.dtsi:29 */
					status = "disabled";             /* in zephyr\boards\nordic\nrf9160dk\nrf9160dk_nrf9160_common_0_14_0.dtsi:30 */
					reg = < 0x20 >;                  /* in zephyr\boards\nordic\nrf9160dk\nrf9160dk_nrf9160_common_0_14_0.dtsi:31 */
					gpio-controller;                 /* in zephyr\boards\nordic\nrf9160dk\nrf9160dk_nrf9160_common_0_14_0.dtsi:32 */
					#gpio-cells = < 0x2 >;           /* in zephyr\boards\nordic\nrf9160dk\nrf9160dk_nrf9160_common_0_14_0.dtsi:33 */
					ngpios = < 0x8 >;                /* in zephyr\boards\nordic\nrf9160dk\nrf9160dk_nrf9160_common_0_14_0.dtsi:34 */
					int-gpios = < &gpio0 0x6 0x11 >; /* in zephyr\boards\nordic\nrf9160dk\nrf9160dk_nrf9160_common_0_14_0.dtsi:35 */
				};
			};

			/* node '/soc/peripheral@40000000/i2c@b000' defined in zephyr\dts\arm\nordic\nrf91_peripherals.dtsi:197 */
			i2c3: i2c@b000 {
				compatible = "nordic,nrf-twim"; /* in zephyr\dts\arm\nordic\nrf91_peripherals.dtsi:203 */
				#address-cells = < 0x1 >;       /* in zephyr\dts\arm\nordic\nrf91_peripherals.dtsi:204 */
				#size-cells = < 0x0 >;          /* in zephyr\dts\arm\nordic\nrf91_peripherals.dtsi:205 */
				reg = < 0xb000 0x1000 >;        /* in zephyr\dts\arm\nordic\nrf91_peripherals.dtsi:206 */
				interrupts = < 0xb 0x1 >;       /* in zephyr\dts\arm\nordic\nrf91_peripherals.dtsi:207 */
				easydma-maxcnt-bits = < 0xd >;  /* in zephyr\dts\arm\nordic\nrf91_peripherals.dtsi:208 */
				status = "disabled";            /* in zephyr\dts\arm\nordic\nrf91_peripherals.dtsi:209 */
				zephyr,pm-device-runtime-auto;  /* in zephyr\dts\arm\nordic\nrf91_peripherals.dtsi:210 */
			};

			/* node '/soc/peripheral@40000000/spi@8000' defined in zephyr\dts\arm\nordic\nrf91_peripherals.dtsi:213 */
			spi0: spi@8000 {
				compatible = "nordic,nrf-spim"; /* in zephyr\dts\arm\nordic\nrf91_peripherals.dtsi:219 */
				#address-cells = < 0x1 >;       /* in zephyr\dts\arm\nordic\nrf91_peripherals.dtsi:220 */
				#size-cells = < 0x0 >;          /* in zephyr\dts\arm\nordic\nrf91_peripherals.dtsi:221 */
				reg = < 0x8000 0x1000 >;        /* in zephyr\dts\arm\nordic\nrf91_peripherals.dtsi:222 */
				interrupts = < 0x8 0x1 >;       /* in zephyr\dts\arm\nordic\nrf91_peripherals.dtsi:223 */
				max-frequency = < 0x7a1200 >;   /* in zephyr\dts\arm\nordic\nrf91_peripherals.dtsi:224 */
				easydma-maxcnt-bits = < 0xd >;  /* in zephyr\dts\arm\nordic\nrf91_peripherals.dtsi:225 */
				status = "disabled";            /* in zephyr\dts\arm\nordic\nrf91_peripherals.dtsi:226 */
			};

			/* node '/soc/peripheral@40000000/spi@9000' defined in zephyr\dts\arm\nordic\nrf91_peripherals.dtsi:229 */
			spi1: spi@9000 {
				compatible = "nordic,nrf-spim"; /* in zephyr\dts\arm\nordic\nrf91_peripherals.dtsi:235 */
				#address-cells = < 0x1 >;       /* in zephyr\dts\arm\nordic\nrf91_peripherals.dtsi:236 */
				#size-cells = < 0x0 >;          /* in zephyr\dts\arm\nordic\nrf91_peripherals.dtsi:237 */
				reg = < 0x9000 0x1000 >;        /* in zephyr\dts\arm\nordic\nrf91_peripherals.dtsi:238 */
				interrupts = < 0x9 0x1 >;       /* in zephyr\dts\arm\nordic\nrf91_peripherals.dtsi:239 */
				max-frequency = < 0x7a1200 >;   /* in zephyr\dts\arm\nordic\nrf91_peripherals.dtsi:240 */
				easydma-maxcnt-bits = < 0xd >;  /* in zephyr\dts\arm\nordic\nrf91_peripherals.dtsi:241 */
				status = "disabled";            /* in zephyr\dts\arm\nordic\nrf91_peripherals.dtsi:242 */
			};

			/* node '/soc/peripheral@40000000/spi@a000' defined in zephyr\dts\arm\nordic\nrf91_peripherals.dtsi:245 */
			spi2: spi@a000 {
				compatible = "nordic,nrf-spim"; /* in zephyr\dts\arm\nordic\nrf91_peripherals.dtsi:251 */
				#address-cells = < 0x1 >;       /* in zephyr\dts\arm\nordic\nrf91_peripherals.dtsi:252 */
				#size-cells = < 0x0 >;          /* in zephyr\dts\arm\nordic\nrf91_peripherals.dtsi:253 */
				reg = < 0xa000 0x1000 >;        /* in zephyr\dts\arm\nordic\nrf91_peripherals.dtsi:254 */
				interrupts = < 0xa 0x1 >;       /* in zephyr\dts\arm\nordic\nrf91_peripherals.dtsi:255 */
				max-frequency = < 0x7a1200 >;   /* in zephyr\dts\arm\nordic\nrf91_peripherals.dtsi:256 */
				easydma-maxcnt-bits = < 0xd >;  /* in zephyr\dts\arm\nordic\nrf91_peripherals.dtsi:257 */
				status = "disabled";            /* in zephyr\dts\arm\nordic\nrf91_peripherals.dtsi:258 */
			};

			/* node '/soc/peripheral@40000000/spi@b000' defined in zephyr\dts\arm\nordic\nrf91_peripherals.dtsi:261 */
			spi3: arduino_spi: spi@b000 {
				#address-cells = < 0x1 >;                /* in zephyr\dts\arm\nordic\nrf91_peripherals.dtsi:268 */
				#size-cells = < 0x0 >;                   /* in zephyr\dts\arm\nordic\nrf91_peripherals.dtsi:269 */
				reg = < 0xb000 0x1000 >;                 /* in zephyr\dts\arm\nordic\nrf91_peripherals.dtsi:270 */
				interrupts = < 0xb 0x1 >;                /* in zephyr\dts\arm\nordic\nrf91_peripherals.dtsi:271 */
				max-frequency = < 0x7a1200 >;            /* in zephyr\dts\arm\nordic\nrf91_peripherals.dtsi:272 */
				easydma-maxcnt-bits = < 0xd >;           /* in zephyr\dts\arm\nordic\nrf91_peripherals.dtsi:273 */
				compatible = "nordic,nrf-spim";          /* in zephyr\boards\nordic\nrf9160dk\nrf9160dk_nrf9160_common.dtsi:220 */
				pinctrl-0 = < &spi3_default >;           /* in zephyr\boards\nordic\nrf9160dk\nrf9160dk_nrf9160_common.dtsi:223 */
				pinctrl-1 = < &spi3_sleep >;             /* in zephyr\boards\nordic\nrf9160dk\nrf9160dk_nrf9160_common.dtsi:224 */
				pinctrl-names = "default",
				                "sleep";                 /* in zephyr\boards\nordic\nrf9160dk\nrf9160dk_nrf9160_common.dtsi:225 */
				cs-gpios = < &arduino_header 0x10 0x1 >,
				           < &gpio0 0x19 0x1 >;          /* in zephyr\boards\nordic\nrf9160dk\nrf9160dk_nrf9160_common_0_14_0.dtsi:40 */
				status = "disabled";                     /* in ..\firmware_dev\app.overlay:143 */

				/* node '/soc/peripheral@40000000/spi@b000/mx25r6435f@1' defined in zephyr\boards\nordic\nrf9160dk\nrf9160dk_nrf9160_common_0_14_0.dtsi:43 */
				mx25r64: mx25r6435f@1 {
					compatible = "jedec,spi-nor";                                                                 /* in zephyr\boards\nordic\nrf9160dk\nrf9160dk_nrf9160_common_0_14_0.dtsi:44 */
					status = "disabled";                                                                          /* in zephyr\boards\nordic\nrf9160dk\nrf9160dk_nrf9160_common_0_14_0.dtsi:45 */
					reg = < 0x1 >;                                                                                /* in zephyr\boards\nordic\nrf9160dk\nrf9160dk_nrf9160_common_0_14_0.dtsi:46 */
					spi-max-frequency = < 0x7a1200 >;                                                             /* in zephyr\boards\nordic\nrf9160dk\nrf9160dk_nrf9160_common_0_14_0.dtsi:47 */
					jedec-id = [ C2 28 17 ];                                                                      /* in zephyr\boards\nordic\nrf9160dk\nrf9160dk_nrf9160_common_0_14_0.dtsi:48 */
					sfdp-bfp = [ E5 20 F1 FF FF FF FF 03 44 EB 08 6B 08 3B 04 BB EE FF FF FF FF FF 00 FF FF FF 00
					             FF 0C 20 0F 52 10 D8 00 FF 23 72 F5 00 82 ED 04 CC 44 83 48 44 30 B0 30 B0 F7 C4
					             D5 5C 00 BE 29 FF F0 D0 FF FF ];                                                 /* in zephyr\boards\nordic\nrf9160dk\nrf9160dk_nrf9160_common_0_14_0.dtsi:49 */
					size = < 0x4000000 >;                                                                         /* in zephyr\boards\nordic\nrf9160dk\nrf9160dk_nrf9160_common_0_14_0.dtsi:55 */
					has-dpd;                                                                                      /* in zephyr\boards\nordic\nrf9160dk\nrf9160dk_nrf9160_common_0_14_0.dtsi:56 */
					t-enter-dpd = < 0x2710 >;                                                                     /* in zephyr\boards\nordic\nrf9160dk\nrf9160dk_nrf9160_common_0_14_0.dtsi:57 */
					t-exit-dpd = < 0x88b8 >;                                                                      /* in zephyr\boards\nordic\nrf9160dk\nrf9160dk_nrf9160_common_0_14_0.dtsi:58 */
				};
			};

			/* node '/soc/peripheral@40000000/pwm@21000' defined in zephyr\dts\arm\nordic\nrf91_peripherals.dtsi:277 */
			pwm0: pwm@21000 {
				compatible = "nordic,nrf-pwm";     /* in zephyr\dts\arm\nordic\nrf91_peripherals.dtsi:278 */
				reg = < 0x21000 0x1000 >;          /* in zephyr\dts\arm\nordic\nrf91_peripherals.dtsi:279 */
				interrupts = < 0x21 0x1 >;         /* in zephyr\dts\arm\nordic\nrf91_peripherals.dtsi:280 */
				#pwm-cells = < 0x3 >;              /* in zephyr\dts\arm\nordic\nrf91_peripherals.dtsi:282 */
				status = "okay";                   /* in ..\firmware_dev\app.overlay:156 */
				pinctrl-0 = < &pwm0_default_alt >; /* in ..\firmware_dev\app.overlay:157 */
				pinctrl-1 = < &pwm0_sleep_alt >;   /* in ..\firmware_dev\app.overlay:158 */
				pinctrl-names = "default",
				                "sleep";           /* in ..\firmware_dev\app.overlay:159 */
				phandle = < 0x14 >;                /* in zephyr\boards\nordic\nrf9160dk\nrf9160dk_nrf9160_common.dtsi:48 */
			};

			/* node '/soc/peripheral@40000000/pwm@22000' defined in zephyr\dts\arm\nordic\nrf91_peripherals.dtsi:285 */
			pwm1: pwm@22000 {
				compatible = "nordic,nrf-pwm"; /* in zephyr\dts\arm\nordic\nrf91_peripherals.dtsi:286 */
				reg = < 0x22000 0x1000 >;      /* in zephyr\dts\arm\nordic\nrf91_peripherals.dtsi:287 */
				interrupts = < 0x22 0x1 >;     /* in zephyr\dts\arm\nordic\nrf91_peripherals.dtsi:288 */
				status = "disabled";           /* in zephyr\dts\arm\nordic\nrf91_peripherals.dtsi:289 */
				#pwm-cells = < 0x3 >;          /* in zephyr\dts\arm\nordic\nrf91_peripherals.dtsi:290 */
			};

			/* node '/soc/peripheral@40000000/pwm@23000' defined in zephyr\dts\arm\nordic\nrf91_peripherals.dtsi:293 */
			pwm2: pwm@23000 {
				compatible = "nordic,nrf-pwm"; /* in zephyr\dts\arm\nordic\nrf91_peripherals.dtsi:294 */
				reg = < 0x23000 0x1000 >;      /* in zephyr\dts\arm\nordic\nrf91_peripherals.dtsi:295 */
				interrupts = < 0x23 0x1 >;     /* in zephyr\dts\arm\nordic\nrf91_peripherals.dtsi:296 */
				status = "disabled";           /* in zephyr\dts\arm\nordic\nrf91_peripherals.dtsi:297 */
				#pwm-cells = < 0x3 >;          /* in zephyr\dts\arm\nordic\nrf91_peripherals.dtsi:298 */
			};

			/* node '/soc/peripheral@40000000/pwm@24000' defined in zephyr\dts\arm\nordic\nrf91_peripherals.dtsi:301 */
			pwm3: pwm@24000 {
				compatible = "nordic,nrf-pwm"; /* in zephyr\dts\arm\nordic\nrf91_peripherals.dtsi:302 */
				reg = < 0x24000 0x1000 >;      /* in zephyr\dts\arm\nordic\nrf91_peripherals.dtsi:303 */
				interrupts = < 0x24 0x1 >;     /* in zephyr\dts\arm\nordic\nrf91_peripherals.dtsi:304 */
				status = "disabled";           /* in zephyr\dts\arm\nordic\nrf91_peripherals.dtsi:305 */
				#pwm-cells = < 0x3 >;          /* in zephyr\dts\arm\nordic\nrf91_peripherals.dtsi:306 */
			};

			/* node '/soc/peripheral@40000000/gpio@842500' defined in zephyr\dts\arm\nordic\nrf91_peripherals.dtsi:309 */
			gpio0: gpio@842500 {
				compatible = "nordic,nrf-gpio"; /* in zephyr\dts\arm\nordic\nrf91_peripherals.dtsi:310 */
				gpio-controller;                /* in zephyr\dts\arm\nordic\nrf91_peripherals.dtsi:311 */
				reg = < 0x842500 0x300 >;       /* in zephyr\dts\arm\nordic\nrf91_peripherals.dtsi:312 */
				#gpio-cells = < 0x2 >;          /* in zephyr\dts\arm\nordic\nrf91_peripherals.dtsi:313 */
				port = < 0x0 >;                 /* in zephyr\dts\arm\nordic\nrf91_peripherals.dtsi:315 */
				gpiote-instance = < &gpiote >;  /* in zephyr\dts\arm\nordic\nrf91_peripherals.dtsi:316 */
				status = "okay";                /* in zephyr\boards\nordic\nrf9160dk\nrf9160dk_nrf9160_common.dtsi:179 */
				phandle = < 0xc >;              /* in zephyr\boards\nordic\nrf9160dk\nrf9160dk_nrf9160_common_0_14_0.dtsi:35 */
			};

			/* node '/soc/peripheral@40000000/rtc@14000' defined in zephyr\dts\arm\nordic\nrf91_peripherals.dtsi:319 */
			rtc0: rtc@14000 {
				compatible = "nordic,nrf-rtc"; /* in zephyr\dts\arm\nordic\nrf91_peripherals.dtsi:320 */
				reg = < 0x14000 0x1000 >;      /* in zephyr\dts\arm\nordic\nrf91_peripherals.dtsi:321 */
				cc-num = < 0x4 >;              /* in zephyr\dts\arm\nordic\nrf91_peripherals.dtsi:322 */
				interrupts = < 0x14 0x1 >;     /* in zephyr\dts\arm\nordic\nrf91_peripherals.dtsi:323 */
				status = "disabled";           /* in zephyr\dts\arm\nordic\nrf91_peripherals.dtsi:324 */
				clock-frequency = < 0x8000 >;  /* in zephyr\dts\arm\nordic\nrf91_peripherals.dtsi:325 */
				prescaler = < 0x1 >;           /* in zephyr\dts\arm\nordic\nrf91_peripherals.dtsi:326 */
			};

			/* node '/soc/peripheral@40000000/rtc@15000' defined in zephyr\dts\arm\nordic\nrf91_peripherals.dtsi:329 */
			rtc1: rtc@15000 {
				compatible = "nordic,nrf-rtc"; /* in zephyr\dts\arm\nordic\nrf91_peripherals.dtsi:330 */
				reg = < 0x15000 0x1000 >;      /* in zephyr\dts\arm\nordic\nrf91_peripherals.dtsi:331 */
				cc-num = < 0x4 >;              /* in zephyr\dts\arm\nordic\nrf91_peripherals.dtsi:332 */
				interrupts = < 0x15 0x1 >;     /* in zephyr\dts\arm\nordic\nrf91_peripherals.dtsi:333 */
				status = "disabled";           /* in zephyr\dts\arm\nordic\nrf91_peripherals.dtsi:334 */
				clock-frequency = < 0x8000 >;  /* in zephyr\dts\arm\nordic\nrf91_peripherals.dtsi:335 */
				prescaler = < 0x1 >;           /* in zephyr\dts\arm\nordic\nrf91_peripherals.dtsi:336 */
			};

			/* node '/soc/peripheral@40000000/clock@5000' defined in zephyr\dts\arm\nordic\nrf91_peripherals.dtsi:339 */
			clock: clock@5000 {
				compatible = "nordic,nrf-clock"; /* in zephyr\dts\arm\nordic\nrf91_peripherals.dtsi:340 */
				reg = < 0x5000 0x1000 >;         /* in zephyr\dts\arm\nordic\nrf91_peripherals.dtsi:341 */
				interrupts = < 0x5 0x1 >;        /* in zephyr\dts\arm\nordic\nrf91_peripherals.dtsi:342 */
				status = "okay";                 /* in zephyr\dts\arm\nordic\nrf91_peripherals.dtsi:343 */
			};

			/* node '/soc/peripheral@40000000/power@5000' defined in zephyr\dts\arm\nordic\nrf91_peripherals.dtsi:346 */
			power: power@5000 {
				compatible = "nordic,nrf-power"; /* in zephyr\dts\arm\nordic\nrf91_peripherals.dtsi:347 */
				reg = < 0x5000 0x1000 >;         /* in zephyr\dts\arm\nordic\nrf91_peripherals.dtsi:348 */
				ranges = < 0x0 0x5000 0x1000 >;  /* in zephyr\dts\arm\nordic\nrf91_peripherals.dtsi:349 */
				interrupts = < 0x5 0x1 >;        /* in zephyr\dts\arm\nordic\nrf91_peripherals.dtsi:350 */
				status = "okay";                 /* in zephyr\dts\arm\nordic\nrf91_peripherals.dtsi:351 */
				#address-cells = < 0x1 >;        /* in zephyr\dts\arm\nordic\nrf91_peripherals.dtsi:352 */
				#size-cells = < 0x1 >;           /* in zephyr\dts\arm\nordic\nrf91_peripherals.dtsi:353 */

				/* node '/soc/peripheral@40000000/power@5000/gpregret1@51c' defined in zephyr\dts\arm\nordic\nrf91_peripherals.dtsi:355 */
				gpregret1: gpregret1@51c {
					#address-cells = < 0x1 >;           /* in zephyr\dts\arm\nordic\nrf91_peripherals.dtsi:356 */
					#size-cells = < 0x1 >;              /* in zephyr\dts\arm\nordic\nrf91_peripherals.dtsi:357 */
					compatible = "nordic,nrf-gpregret"; /* in zephyr\dts\arm\nordic\nrf91_peripherals.dtsi:358 */
					reg = < 0x51c 0x1 >;                /* in zephyr\dts\arm\nordic\nrf91_peripherals.dtsi:359 */
					status = "okay";                    /* in zephyr\dts\arm\nordic\nrf91_peripherals.dtsi:360 */
				};

				/* node '/soc/peripheral@40000000/power@5000/gpregret2@520' defined in zephyr\dts\arm\nordic\nrf91_peripherals.dtsi:363 */
				gpregret2: gpregret2@520 {
					#address-cells = < 0x1 >;           /* in zephyr\dts\arm\nordic\nrf91_peripherals.dtsi:364 */
					#size-cells = < 0x1 >;              /* in zephyr\dts\arm\nordic\nrf91_peripherals.dtsi:365 */
					compatible = "nordic,nrf-gpregret"; /* in zephyr\dts\arm\nordic\nrf91_peripherals.dtsi:366 */
					reg = < 0x520 0x1 >;                /* in zephyr\dts\arm\nordic\nrf91_peripherals.dtsi:367 */
					status = "okay";                    /* in zephyr\dts\arm\nordic\nrf91_peripherals.dtsi:368 */
				};
			};

			/* node '/soc/peripheral@40000000/watchdog@18000' defined in zephyr\dts\arm\nordic\nrf91_peripherals.dtsi:372 */
			wdt: wdt0: watchdog@18000 {
				compatible = "nordic,nrf-wdt"; /* in zephyr\dts\arm\nordic\nrf91_peripherals.dtsi:373 */
				reg = < 0x18000 0x1000 >;      /* in zephyr\dts\arm\nordic\nrf91_peripherals.dtsi:374 */
				interrupts = < 0x18 0x1 >;     /* in zephyr\dts\arm\nordic\nrf91_peripherals.dtsi:375 */
				status = "okay";               /* in zephyr\dts\arm\nordic\nrf91_peripherals.dtsi:376 */
			};

			/* node '/soc/peripheral@40000000/timer@f000' defined in zephyr\dts\arm\nordic\nrf91_peripherals.dtsi:379 */
			timer0: timer@f000 {
				compatible = "nordic,nrf-timer"; /* in zephyr\dts\arm\nordic\nrf91_peripherals.dtsi:380 */
				status = "disabled";             /* in zephyr\dts\arm\nordic\nrf91_peripherals.dtsi:381 */
				reg = < 0xf000 0x1000 >;         /* in zephyr\dts\arm\nordic\nrf91_peripherals.dtsi:382 */
				cc-num = < 0x6 >;                /* in zephyr\dts\arm\nordic\nrf91_peripherals.dtsi:383 */
				max-bit-width = < 0x20 >;        /* in zephyr\dts\arm\nordic\nrf91_peripherals.dtsi:384 */
				interrupts = < 0xf 0x1 >;        /* in zephyr\dts\arm\nordic\nrf91_peripherals.dtsi:385 */
				prescaler = < 0x0 >;             /* in zephyr\dts\arm\nordic\nrf91_peripherals.dtsi:386 */
			};

			/* node '/soc/peripheral@40000000/timer@10000' defined in zephyr\dts\arm\nordic\nrf91_peripherals.dtsi:389 */
			timer1: timer@10000 {
				compatible = "nordic,nrf-timer"; /* in zephyr\dts\arm\nordic\nrf91_peripherals.dtsi:390 */
				status = "disabled";             /* in zephyr\dts\arm\nordic\nrf91_peripherals.dtsi:391 */
				reg = < 0x10000 0x1000 >;        /* in zephyr\dts\arm\nordic\nrf91_peripherals.dtsi:392 */
				cc-num = < 0x6 >;                /* in zephyr\dts\arm\nordic\nrf91_peripherals.dtsi:393 */
				max-bit-width = < 0x20 >;        /* in zephyr\dts\arm\nordic\nrf91_peripherals.dtsi:394 */
				interrupts = < 0x10 0x1 >;       /* in zephyr\dts\arm\nordic\nrf91_peripherals.dtsi:395 */
				prescaler = < 0x0 >;             /* in zephyr\dts\arm\nordic\nrf91_peripherals.dtsi:396 */
				phandle = < 0x13 >;              /* in zephyr\dts\vendor\nordic\nrf_common.dtsi:42 */
			};

			/* node '/soc/peripheral@40000000/timer@11000' defined in zephyr\dts\arm\nordic\nrf91_peripherals.dtsi:399 */
			timer2: timer@11000 {
				compatible = "nordic,nrf-timer"; /* in zephyr\dts\arm\nordic\nrf91_peripherals.dtsi:400 */
				status = "disabled";             /* in zephyr\dts\arm\nordic\nrf91_peripherals.dtsi:401 */
				reg = < 0x11000 0x1000 >;        /* in zephyr\dts\arm\nordic\nrf91_peripherals.dtsi:402 */
				cc-num = < 0x6 >;                /* in zephyr\dts\arm\nordic\nrf91_peripherals.dtsi:403 */
				max-bit-width = < 0x20 >;        /* in zephyr\dts\arm\nordic\nrf91_peripherals.dtsi:404 */
				interrupts = < 0x11 0x1 >;       /* in zephyr\dts\arm\nordic\nrf91_peripherals.dtsi:405 */
				prescaler = < 0x0 >;             /* in zephyr\dts\arm\nordic\nrf91_peripherals.dtsi:406 */
			};
		};

		/* node '/soc/gpiote@40031000' defined in zephyr\dts\arm\nordic\nrf91ns.dtsi:54 */
		gpiote: gpiote1: gpiote@40031000 {
			compatible = "nordic,nrf-gpiote"; /* in zephyr\dts\arm\nordic\nrf91ns.dtsi:55 */
			reg = < 0x40031000 0x1000 >;      /* in zephyr\dts\arm\nordic\nrf91ns.dtsi:56 */
			interrupts = < 0x31 0x5 >;        /* in zephyr\dts\arm\nordic\nrf91ns.dtsi:57 */
			instance = < 0x1 >;               /* in zephyr\dts\arm\nordic\nrf91ns.dtsi:59 */
			status = "okay";                  /* in zephyr\boards\nordic\nrf9160dk\nrf9160dk_nrf9160_common.dtsi:175 */
			phandle = < 0x12 >;               /* in zephyr\dts\arm\nordic\nrf91_peripherals.dtsi:316 */
		};
	};

	/* node '/pin-controller' defined in zephyr\dts\vendor\nordic\nrf_common.dtsi:26 */
	pinctrl: pin-controller {
		compatible = "nordic,nrf-pinctrl"; /* in zephyr\dts\vendor\nordic\nrf_common.dtsi:31 */

		/* node '/pin-controller/uart0_default' defined in zephyr\boards\nordic\nrf9160dk\nrf9160dk_nrf9160_common-pinctrl.dtsi:7 */
		uart0_default: uart0_default {
			phandle = < 0x2 >; /* in zephyr\boards\nordic\nrf9160dk\nrf9160dk_nrf9160_common.dtsi:185 */

			/* node '/pin-controller/uart0_default/group1' defined in zephyr\boards\nordic\nrf9160dk\nrf9160dk_nrf9160_common-pinctrl.dtsi:8 */
			group1 {
				psels = < 0x1d >,
				        < 0x200001b >; /* in zephyr\boards\nordic\nrf9160dk\nrf9160dk_nrf9160_common-pinctrl.dtsi:9 */
			};

			/* node '/pin-controller/uart0_default/group2' defined in zephyr\boards\nordic\nrf9160dk\nrf9160dk_nrf9160_common-pinctrl.dtsi:13 */
			group2 {
				psels = < 0x100001c >,
				        < 0x300001a >; /* in zephyr\boards\nordic\nrf9160dk\nrf9160dk_nrf9160_common-pinctrl.dtsi:14 */
				bias-pull-up;          /* in zephyr\boards\nordic\nrf9160dk\nrf9160dk_nrf9160_common-pinctrl.dtsi:16 */
			};
		};

		/* node '/pin-controller/uart0_sleep' defined in zephyr\boards\nordic\nrf9160dk\nrf9160dk_nrf9160_common-pinctrl.dtsi:20 */
		uart0_sleep: uart0_sleep {
			phandle = < 0x3 >; /* in zephyr\boards\nordic\nrf9160dk\nrf9160dk_nrf9160_common.dtsi:186 */

			/* node '/pin-controller/uart0_sleep/group1' defined in zephyr\boards\nordic\nrf9160dk\nrf9160dk_nrf9160_common-pinctrl.dtsi:21 */
			group1 {
				psels = < 0x1d >,
				        < 0x100001c >,
				        < 0x200001b >,
				        < 0x300001a >; /* in zephyr\boards\nordic\nrf9160dk\nrf9160dk_nrf9160_common-pinctrl.dtsi:22 */
				low-power-enable;      /* in zephyr\boards\nordic\nrf9160dk\nrf9160dk_nrf9160_common-pinctrl.dtsi:26 */
			};
		};

		/* node '/pin-controller/uart1_default' defined in zephyr\boards\nordic\nrf9160dk\nrf9160dk_nrf9160_common-pinctrl.dtsi:30 */
		uart1_default: uart1_default {
			phandle = < 0x4 >; /* in zephyr\boards\nordic\nrf9160dk\nrf9160dk_nrf9160_common.dtsi:193 */

			/* node '/pin-controller/uart1_default/group1' defined in zephyr\boards\nordic\nrf9160dk\nrf9160dk_nrf9160_common-pinctrl.dtsi:31 */
			group1 {
				psels = < 0x1 >,
				        < 0x200000e >; /* in zephyr\boards\nordic\nrf9160dk\nrf9160dk_nrf9160_common-pinctrl.dtsi:32 */
			};

			/* node '/pin-controller/uart1_default/group2' defined in zephyr\boards\nordic\nrf9160dk\nrf9160dk_nrf9160_common-pinctrl.dtsi:36 */
			group2 {
				psels = < 0x1000000 >,
				        < 0x300000f >; /* in zephyr\boards\nordic\nrf9160dk\nrf9160dk_nrf9160_common-pinctrl.dtsi:37 */
				bias-pull-up;          /* in zephyr\boards\nordic\nrf9160dk\nrf9160dk_nrf9160_common-pinctrl.dtsi:39 */
			};
		};

		/* node '/pin-controller/uart1_sleep' defined in zephyr\boards\nordic\nrf9160dk\nrf9160dk_nrf9160_common-pinctrl.dtsi:43 */
		uart1_sleep: uart1_sleep {
			phandle = < 0x5 >; /* in zephyr\boards\nordic\nrf9160dk\nrf9160dk_nrf9160_common.dtsi:194 */

			/* node '/pin-controller/uart1_sleep/group1' defined in zephyr\boards\nordic\nrf9160dk\nrf9160dk_nrf9160_common-pinctrl.dtsi:44 */
			group1 {
				psels = < 0x1 >,
				        < 0x1000000 >,
				        < 0x200000e >,
				        < 0x300000f >; /* in zephyr\boards\nordic\nrf9160dk\nrf9160dk_nrf9160_common-pinctrl.dtsi:45 */
				low-power-enable;      /* in zephyr\boards\nordic\nrf9160dk\nrf9160dk_nrf9160_common-pinctrl.dtsi:49 */
			};
		};

		/* node '/pin-controller/uart2_default' defined in zephyr\boards\nordic\nrf9160dk\nrf9160dk_nrf9160_common-pinctrl.dtsi:53 */
		uart2_default: uart2_default {

			/* node '/pin-controller/uart2_default/group1' defined in zephyr\boards\nordic\nrf9160dk\nrf9160dk_nrf9160_common-pinctrl.dtsi:54 */
			group1 {
				psels = < 0x18 >,
				        < 0x1000017 >; /* in zephyr\boards\nordic\nrf9160dk\nrf9160dk_nrf9160_common-pinctrl.dtsi:55 */
			};
		};

		/* node '/pin-controller/uart2_sleep' defined in zephyr\boards\nordic\nrf9160dk\nrf9160dk_nrf9160_common-pinctrl.dtsi:60 */
		uart2_sleep: uart2_sleep {

			/* node '/pin-controller/uart2_sleep/group1' defined in zephyr\boards\nordic\nrf9160dk\nrf9160dk_nrf9160_common-pinctrl.dtsi:61 */
			group1 {
				psels = < 0x18 >,
				        < 0x1000017 >; /* in zephyr\boards\nordic\nrf9160dk\nrf9160dk_nrf9160_common-pinctrl.dtsi:62 */
				low-power-enable;      /* in zephyr\boards\nordic\nrf9160dk\nrf9160dk_nrf9160_common-pinctrl.dtsi:64 */
			};
		};

		/* node '/pin-controller/i2c2_default' defined in zephyr\boards\nordic\nrf9160dk\nrf9160dk_nrf9160_common-pinctrl.dtsi:68 */
		i2c2_default: i2c2_default {
			phandle = < 0xa >; /* in zephyr\boards\nordic\nrf9160dk\nrf9160dk_nrf9160_common.dtsi:207 */

			/* node '/pin-controller/i2c2_default/group1' defined in zephyr\boards\nordic\nrf9160dk\nrf9160dk_nrf9160_common-pinctrl.dtsi:69 */
			group1 {
				psels = < 0xc00001e >,
				        < 0xb00001f >; /* in zephyr\boards\nordic\nrf9160dk\nrf9160dk_nrf9160_common-pinctrl.dtsi:70 */
			};
		};

		/* node '/pin-controller/i2c2_sleep' defined in zephyr\boards\nordic\nrf9160dk\nrf9160dk_nrf9160_common-pinctrl.dtsi:75 */
		i2c2_sleep: i2c2_sleep {
			phandle = < 0xb >; /* in zephyr\boards\nordic\nrf9160dk\nrf9160dk_nrf9160_common.dtsi:208 */

			/* node '/pin-controller/i2c2_sleep/group1' defined in zephyr\boards\nordic\nrf9160dk\nrf9160dk_nrf9160_common-pinctrl.dtsi:76 */
			group1 {
				psels = < 0xc00001e >,
				        < 0xb00001f >; /* in zephyr\boards\nordic\nrf9160dk\nrf9160dk_nrf9160_common-pinctrl.dtsi:77 */
				low-power-enable;      /* in zephyr\boards\nordic\nrf9160dk\nrf9160dk_nrf9160_common-pinctrl.dtsi:79 */
			};
		};

		/* node '/pin-controller/pwm0_default' defined in zephyr\boards\nordic\nrf9160dk\nrf9160dk_nrf9160_common-pinctrl.dtsi:83 */
		pwm0_default: pwm0_default {

			/* node '/pin-controller/pwm0_default/group1' defined in zephyr\boards\nordic\nrf9160dk\nrf9160dk_nrf9160_common-pinctrl.dtsi:84 */
			group1 {
				psels = < 0x16000002 >; /* in zephyr\boards\nordic\nrf9160dk\nrf9160dk_nrf9160_common-pinctrl.dtsi:85 */
			};
		};

		/* node '/pin-controller/pwm0_sleep' defined in zephyr\boards\nordic\nrf9160dk\nrf9160dk_nrf9160_common-pinctrl.dtsi:89 */
		pwm0_sleep: pwm0_sleep {

			/* node '/pin-controller/pwm0_sleep/group1' defined in zephyr\boards\nordic\nrf9160dk\nrf9160dk_nrf9160_common-pinctrl.dtsi:90 */
			group1 {
				psels = < 0x16000002 >; /* in zephyr\boards\nordic\nrf9160dk\nrf9160dk_nrf9160_common-pinctrl.dtsi:91 */
				low-power-enable;       /* in zephyr\boards\nordic\nrf9160dk\nrf9160dk_nrf9160_common-pinctrl.dtsi:92 */
			};
		};

		/* node '/pin-controller/spi3_default' defined in zephyr\boards\nordic\nrf9160dk\nrf9160dk_nrf9160_common-pinctrl.dtsi:96 */
		spi3_default: spi3_default {
			phandle = < 0xd >; /* in zephyr\boards\nordic\nrf9160dk\nrf9160dk_nrf9160_common.dtsi:223 */

			/* node '/pin-controller/spi3_default/group1' defined in zephyr\boards\nordic\nrf9160dk\nrf9160dk_nrf9160_common-pinctrl.dtsi:97 */
			group1 {
				psels = < 0x400000d >,
				        < 0x600000c >,
				        < 0x500000b >;       /* in zephyr\boards\nordic\nrf9160dk\nrf9160dk_nrf9160_common-pinctrl.dtsi:98 */
				nordic,drive-mode = < 0x3 >; /* in zephyr\boards\nordic\nrf9160dk\nrf9160dk_nrf9160_common-pinctrl.dtsi:101 */
			};
		};

		/* node '/pin-controller/spi3_sleep' defined in zephyr\boards\nordic\nrf9160dk\nrf9160dk_nrf9160_common-pinctrl.dtsi:105 */
		spi3_sleep: spi3_sleep {
			phandle = < 0xe >; /* in zephyr\boards\nordic\nrf9160dk\nrf9160dk_nrf9160_common.dtsi:224 */

			/* node '/pin-controller/spi3_sleep/group1' defined in zephyr\boards\nordic\nrf9160dk\nrf9160dk_nrf9160_common-pinctrl.dtsi:106 */
			group1 {
				psels = < 0x400000d >,
				        < 0x600000c >,
				        < 0x500000b >; /* in zephyr\boards\nordic\nrf9160dk\nrf9160dk_nrf9160_common-pinctrl.dtsi:107 */
				low-power-enable;      /* in zephyr\boards\nordic\nrf9160dk\nrf9160dk_nrf9160_common-pinctrl.dtsi:110 */
			};
		};

		/* node '/pin-controller/uart2_default_alt' defined in ..\firmware_dev\app.overlay:71 */
		uart2_default_alt: uart2_default_alt {
			phandle = < 0x6 >; /* in ..\firmware_dev\app.overlay:165 */

			/* node '/pin-controller/uart2_default_alt/group1' defined in ..\firmware_dev\app.overlay:72 */
			group1 {
				psels = < 0x1d >; /* in ..\firmware_dev\app.overlay:73 */
			};

			/* node '/pin-controller/uart2_default_alt/group2' defined in ..\firmware_dev\app.overlay:75 */
			group2 {
				psels = < 0x100001c >; /* in ..\firmware_dev\app.overlay:76 */
				bias-pull-up;          /* in ..\firmware_dev\app.overlay:77 */
			};
		};

		/* node '/pin-controller/uart2_sleep_alt' defined in ..\firmware_dev\app.overlay:81 */
		uart2_sleep_alt: uart2_sleep_alt {
			phandle = < 0x7 >; /* in ..\firmware_dev\app.overlay:166 */

			/* node '/pin-controller/uart2_sleep_alt/group1' defined in ..\firmware_dev\app.overlay:82 */
			group1 {
				psels = < 0x1d >,
				        < 0x100001c >; /* in ..\firmware_dev\app.overlay:83 */
				low-power-enable;      /* in ..\firmware_dev\app.overlay:85 */
			};
		};

		/* node '/pin-controller/uart3_default_alt' defined in ..\firmware_dev\app.overlay:89 */
		uart3_default_alt: uart3_default_alt {
			phandle = < 0x8 >; /* in ..\firmware_dev\app.overlay:149 */

			/* node '/pin-controller/uart3_default_alt/group1' defined in ..\firmware_dev\app.overlay:90 */
			group1 {
				psels = < 0x1 >; /* in ..\firmware_dev\app.overlay:91 */
			};

			/* node '/pin-controller/uart3_default_alt/group2' defined in ..\firmware_dev\app.overlay:93 */
			group2 {
				psels = < 0x1000000 >; /* in ..\firmware_dev\app.overlay:94 */
				bias-pull-up;          /* in ..\firmware_dev\app.overlay:95 */
			};
		};

		/* node '/pin-controller/uart3_sleep_alt' defined in ..\firmware_dev\app.overlay:99 */
		uart3_sleep_alt: uart3_sleep_alt {
			phandle = < 0x9 >; /* in ..\firmware_dev\app.overlay:150 */

			/* node '/pin-controller/uart3_sleep_alt/group1' defined in ..\firmware_dev\app.overlay:100 */
			group1 {
				psels = < 0x1 >,
				        < 0x1000000 >; /* in ..\firmware_dev\app.overlay:101 */
				low-power-enable;      /* in ..\firmware_dev\app.overlay:103 */
			};
		};

		/* node '/pin-controller/pwm0_default_alt' defined in ..\firmware_dev\app.overlay:110 */
		pwm0_default_alt: pwm0_default_alt {
			phandle = < 0x10 >; /* in ..\firmware_dev\app.overlay:157 */

			/* node '/pin-controller/pwm0_default_alt/group1' defined in ..\firmware_dev\app.overlay:111 */
			group1 {
				psels = < 0x16000005 >,
				        < 0x17000007 >; /* in ..\firmware_dev\app.overlay:112 */
			};
		};

		/* node '/pin-controller/pwm0_sleep_alt' defined in ..\firmware_dev\app.overlay:117 */
		pwm0_sleep_alt: pwm0_sleep_alt {
			phandle = < 0x11 >; /* in ..\firmware_dev\app.overlay:158 */

			/* node '/pin-controller/pwm0_sleep_alt/group1' defined in ..\firmware_dev\app.overlay:118 */
			group1 {
				psels = < 0x16000005 >,
				        < 0x17000007 >; /* in ..\firmware_dev\app.overlay:119 */
				low-power-enable;       /* in ..\firmware_dev\app.overlay:121 */
			};
		};
	};

	/* node '/entropy_bt_hci' defined in zephyr\dts\vendor\nordic\nrf_common.dtsi:34 */
	rng_hci: entropy_bt_hci {
		compatible = "zephyr,bt-hci-entropy"; /* in zephyr\dts\vendor\nordic\nrf_common.dtsi:35 */
		status = "disabled";                  /* in zephyr\dts\vendor\nordic\nrf_common.dtsi:36 */
	};

	/* node '/sw-pwm' defined in zephyr\dts\vendor\nordic\nrf_common.dtsi:39 */
	sw_pwm: sw-pwm {
		compatible = "nordic,nrf-sw-pwm"; /* in zephyr\dts\vendor\nordic\nrf_common.dtsi:40 */
		status = "disabled";              /* in zephyr\dts\vendor\nordic\nrf_common.dtsi:41 */
		generator = < &timer1 >;          /* in zephyr\dts\vendor\nordic\nrf_common.dtsi:42 */
		clock-prescaler = < 0x0 >;        /* in zephyr\dts\vendor\nordic\nrf_common.dtsi:43 */
		#pwm-cells = < 0x3 >;             /* in zephyr\dts\vendor\nordic\nrf_common.dtsi:44 */
	};

	/* node '/cpus' defined in zephyr\dts\arm\nordic\nrf91ns.dtsi:12 */
	cpus {
		#address-cells = < 0x1 >; /* in zephyr\dts\arm\nordic\nrf91ns.dtsi:13 */
		#size-cells = < 0x0 >;    /* in zephyr\dts\arm\nordic\nrf91ns.dtsi:14 */

		/* node '/cpus/cpu@0' defined in zephyr\dts\arm\nordic\nrf91ns.dtsi:16 */
		cpu@0 {
			device_type = "cpu";            /* in zephyr\dts\arm\nordic\nrf91ns.dtsi:17 */
			compatible = "arm,cortex-m33f"; /* in zephyr\dts\arm\nordic\nrf91ns.dtsi:18 */
			reg = < 0x0 >;                  /* in zephyr\dts\arm\nordic\nrf91ns.dtsi:19 */
			#address-cells = < 0x1 >;       /* in zephyr\dts\arm\nordic\nrf91ns.dtsi:20 */
			#size-cells = < 0x1 >;          /* in zephyr\dts\arm\nordic\nrf91ns.dtsi:21 */

			/* node '/cpus/cpu@0/mpu@e000ed90' defined in zephyr\dts\arm\nordic\nrf91ns.dtsi:23 */
			mpu: mpu@e000ed90 {
				compatible = "arm,armv8m-mpu"; /* in zephyr\dts\arm\nordic\nrf91ns.dtsi:24 */
				reg = < 0xe000ed90 0x40 >;     /* in zephyr\dts\arm\nordic\nrf91ns.dtsi:25 */
			};
		};
	};

	/* node '/psa-rng' defined in zephyr\dts\arm\nordic\nrf91ns.dtsi:63 */
	psa_rng: psa-rng {
		compatible = "zephyr,psa-crypto-rng"; /* in zephyr\dts\arm\nordic\nrf91ns.dtsi:64 */
		status = "okay";                      /* in zephyr\dts\arm\nordic\nrf91ns.dtsi:65 */
	};

	/* node '/leds' defined in zephyr\boards\nordic\nrf9160dk\nrf9160dk_nrf9160_common.dtsi:20 */
	leds {
		compatible = "gpio-leds"; /* in zephyr\boards\nordic\nrf9160dk\nrf9160dk_nrf9160_common.dtsi:21 */

		/* node '/leds/led_0' defined in zephyr\boards\nordic\nrf9160dk\nrf9160dk_nrf9160_common.dtsi:23 */
		led0: led_0 {
			gpios = < &gpio0 0x2 0x0 >; /* in zephyr\boards\nordic\nrf9160dk\nrf9160dk_nrf9160_common.dtsi:24 */
			label = "Green LED 1";      /* in zephyr\boards\nordic\nrf9160dk\nrf9160dk_nrf9160_common.dtsi:25 */
		};

		/* node '/leds/led_1' defined in zephyr\boards\nordic\nrf9160dk\nrf9160dk_nrf9160_common.dtsi:28 */
		led1: led_1 {
			gpios = < &gpio0 0x3 0x0 >; /* in zephyr\boards\nordic\nrf9160dk\nrf9160dk_nrf9160_common.dtsi:29 */
			label = "Green LED 2";      /* in zephyr\boards\nordic\nrf9160dk\nrf9160dk_nrf9160_common.dtsi:30 */
		};

		/* node '/leds/led_2' defined in zephyr\boards\nordic\nrf9160dk\nrf9160dk_nrf9160_common.dtsi:33 */
		led2: led_2 {
			gpios = < &gpio0 0x4 0x0 >; /* in zephyr\boards\nordic\nrf9160dk\nrf9160dk_nrf9160_common.dtsi:34 */
			label = "Green LED 3";      /* in zephyr\boards\nordic\nrf9160dk\nrf9160dk_nrf9160_common.dtsi:35 */
		};

		/* node '/leds/led_3' defined in zephyr\boards\nordic\nrf9160dk\nrf9160dk_nrf9160_common.dtsi:38 */
		led3: led_3 {
			gpios = < &gpio0 0x5 0x0 >; /* in zephyr\boards\nordic\nrf9160dk\nrf9160dk_nrf9160_common.dtsi:39 */
			label = "Green LED 4";      /* in zephyr\boards\nordic\nrf9160dk\nrf9160dk_nrf9160_common.dtsi:40 */
		};
	};

	/* node '/pwmleds' defined in zephyr\boards\nordic\nrf9160dk\nrf9160dk_nrf9160_common.dtsi:44 */
	pwmleds {
		compatible = "pwm-leds"; /* in zephyr\boards\nordic\nrf9160dk\nrf9160dk_nrf9160_common.dtsi:45 */

		/* node '/pwmleds/pwm_led_0' defined in zephyr\boards\nordic\nrf9160dk\nrf9160dk_nrf9160_common.dtsi:47 */
		pwm_led0: pwm_led_0 {
			pwms = < &pwm0 0x0 0x1312d00 0x0 >; /* in zephyr\boards\nordic\nrf9160dk\nrf9160dk_nrf9160_common.dtsi:48 */
		};
	};

	/* node '/buttons' defined in zephyr\boards\nordic\nrf9160dk\nrf9160dk_nrf9160_common.dtsi:52 */
	buttons {
		compatible = "gpio-keys"; /* in zephyr\boards\nordic\nrf9160dk\nrf9160dk_nrf9160_common.dtsi:60 */

		/* node '/buttons/button_0' defined in zephyr\boards\nordic\nrf9160dk\nrf9160dk_nrf9160_common.dtsi:62 */
		button0: button_0 {
			gpios = < &gpio0 0x6 0x11 >; /* in zephyr\boards\nordic\nrf9160dk\nrf9160dk_nrf9160_common.dtsi:63 */
			label = "Push button 1";     /* in zephyr\boards\nordic\nrf9160dk\nrf9160dk_nrf9160_common.dtsi:64 */
			zephyr,code = < 0xb >;       /* in zephyr\boards\nordic\nrf9160dk\nrf9160dk_nrf9160_common.dtsi:65 */
		};

		/* node '/buttons/button_1' defined in zephyr\boards\nordic\nrf9160dk\nrf9160dk_nrf9160_common.dtsi:68 */
		button1: button_1 {
			gpios = < &gpio0 0x7 0x11 >; /* in zephyr\boards\nordic\nrf9160dk\nrf9160dk_nrf9160_common.dtsi:69 */
			label = "Push button 2";     /* in zephyr\boards\nordic\nrf9160dk\nrf9160dk_nrf9160_common.dtsi:70 */
			zephyr,code = < 0x2 >;       /* in zephyr\boards\nordic\nrf9160dk\nrf9160dk_nrf9160_common.dtsi:71 */
		};

		/* node '/buttons/button_2' defined in zephyr\boards\nordic\nrf9160dk\nrf9160dk_nrf9160_common.dtsi:74 */
		button2: button_2 {
			gpios = < &gpio0 0x8 0x11 >; /* in zephyr\boards\nordic\nrf9160dk\nrf9160dk_nrf9160_common.dtsi:75 */
			label = "Switch 1";          /* in zephyr\boards\nordic\nrf9160dk\nrf9160dk_nrf9160_common.dtsi:76 */
			zephyr,code = < 0x3 >;       /* in zephyr\boards\nordic\nrf9160dk\nrf9160dk_nrf9160_common.dtsi:77 */
			status = "disabled";         /* in ..\firmware_dev\app.overlay:63 */
		};

		/* node '/buttons/button_3' defined in zephyr\boards\nordic\nrf9160dk\nrf9160dk_nrf9160_common.dtsi:80 */
		button3: button_3 {
			gpios = < &gpio0 0x9 0x11 >; /* in zephyr\boards\nordic\nrf9160dk\nrf9160dk_nrf9160_common.dtsi:81 */
			label = "Switch 2";          /* in zephyr\boards\nordic\nrf9160dk\nrf9160dk_nrf9160_common.dtsi:82 */
			zephyr,code = < 0x4 >;       /* in zephyr\boards\nordic\nrf9160dk\nrf9160dk_nrf9160_common.dtsi:83 */
			status = "disabled";         /* in ..\firmware_dev\app.overlay:67 */
		};
	};

	/* node '/gpio-interface' defined in zephyr\boards\nordic\nrf9160dk\nrf9160dk_nrf9160_common.dtsi:87 */
	interface_to_nrf52840: gpio-interface {
		compatible = "nordic,nrf9160dk-nrf52840-interface"; /* in zephyr\boards\nordic\nrf9160dk\nrf9160dk_nrf9160_common.dtsi:88 */
		#gpio-cells = < 0x2 >;                              /* in zephyr\boards\nordic\nrf9160dk\nrf9160dk_nrf9160_common.dtsi:89 */
		gpio-map-mask = < 0xf 0x0 >;                        /* in zephyr\boards\nordic\nrf9160dk\nrf9160dk_nrf9160_common.dtsi:90 */
		gpio-map-pass-thru = < 0x0 0xffffffff >;            /* in zephyr\boards\nordic\nrf9160dk\nrf9160dk_nrf9160_common.dtsi:91 */
		gpio-map = < 0x0 0x0 &gpio0 0x11 0x0 >,
		           < 0x1 0x0 &gpio0 0x12 0x0 >,
		           < 0x2 0x0 &gpio0 0x13 0x0 >,
		           < 0x3 0x0 &gpio0 0x15 0x0 >,
		           < 0x4 0x0 &gpio0 0x16 0x0 >,
		           < 0x5 0x0 &gpio0 0x17 0x0 >,
		           < 0x9 0x0 &gpio0 0x18 0x0 >;             /* in zephyr\boards\nordic\nrf9160dk\nrf9160dk_nrf9160_common_0_14_0.dtsi:8 */
		phandle = < 0x15 >;                                 /* in zephyr\boards\nordic\nrf9160dk\nrf9160dk_nrf9160_common_0_14_0.dtsi:21 */
	};

	/* node '/gpio-reset' defined in zephyr\boards\nordic\nrf9160dk\nrf9160dk_nrf9160_common.dtsi:103 */
	nrf52840_reset: gpio-reset {
		compatible = "nordic,nrf9160dk-nrf52840-reset"; /* in zephyr\boards\nordic\nrf9160dk\nrf9160dk_nrf9160_common.dtsi:104 */
		status = "disabled";                            /* in zephyr\boards\nordic\nrf9160dk\nrf9160dk_nrf9160_common.dtsi:105 */
		gpios = < &interface_to_nrf52840 0x9 0x1 >;     /* in zephyr\boards\nordic\nrf9160dk\nrf9160dk_nrf9160_common_0_14_0.dtsi:21 */
	};

	/* node '/connector' defined in zephyr\boards\nordic\nrf9160dk\nrf9160dk_nrf9160_common.dtsi:113 */
	arduino_header: connector {
		compatible = "arduino-header-r3";          /* in zephyr\boards\nordic\nrf9160dk\nrf9160dk_nrf9160_common.dtsi:114 */
		#gpio-cells = < 0x2 >;                     /* in zephyr\boards\nordic\nrf9160dk\nrf9160dk_nrf9160_common.dtsi:115 */
		gpio-map-mask = < 0xffffffff 0xffffffc0 >; /* in zephyr\boards\nordic\nrf9160dk\nrf9160dk_nrf9160_common.dtsi:116 */
		gpio-map-pass-thru = < 0x0 0x3f >;         /* in zephyr\boards\nordic\nrf9160dk\nrf9160dk_nrf9160_common.dtsi:117 */
		gpio-map = < 0x0 0x0 &gpio0 0xe 0x0 >,
		           < 0x1 0x0 &gpio0 0xf 0x0 >,
		           < 0x2 0x0 &gpio0 0x10 0x0 >,
		           < 0x3 0x0 &gpio0 0x11 0x0 >,
		           < 0x4 0x0 &gpio0 0x12 0x0 >,
		           < 0x5 0x0 &gpio0 0x13 0x0 >,
		           < 0x6 0x0 &gpio0 0x0 0x0 >,
		           < 0x7 0x0 &gpio0 0x1 0x0 >,
		           < 0x8 0x0 &gpio0 0x2 0x0 >,
		           < 0x9 0x0 &gpio0 0x3 0x0 >,
		           < 0xa 0x0 &gpio0 0x4 0x0 >,
		           < 0xb 0x0 &gpio0 0x5 0x0 >,
		           < 0xc 0x0 &gpio0 0x6 0x0 >,
		           < 0xd 0x0 &gpio0 0x7 0x0 >,
		           < 0xe 0x0 &gpio0 0x8 0x0 >,
		           < 0xf 0x0 &gpio0 0x9 0x0 >,
		           < 0x10 0x0 &gpio0 0xa 0x0 >,
		           < 0x11 0x0 &gpio0 0xb 0x0 >,
		           < 0x12 0x0 &gpio0 0xc 0x0 >,
		           < 0x13 0x0 &gpio0 0xd 0x0 >,
		           < 0x14 0x0 &gpio0 0x1e 0x0 >,
		           < 0x15 0x0 &gpio0 0x1f 0x0 >;   /* in zephyr\boards\nordic\nrf9160dk\nrf9160dk_nrf9160_common.dtsi:118 */
		phandle = < 0xf >;                         /* in zephyr\boards\nordic\nrf9160dk\nrf9160dk_nrf9160_common_0_14_0.dtsi:40 */
	};

	/* node '/analog-connector' defined in zephyr\boards\nordic\nrf9160dk\nrf9160dk_nrf9160_common.dtsi:142 */
	arduino_adc: analog-connector {
		compatible = "arduino,uno-adc";    /* in zephyr\boards\nordic\nrf9160dk\nrf9160dk_nrf9160_common.dtsi:143 */
		#io-channel-cells = < 0x1 >;       /* in zephyr\boards\nordic\nrf9160dk\nrf9160dk_nrf9160_common.dtsi:144 */
		io-channel-map = < 0x0 &adc 0x1 >,
		                 < 0x1 &adc 0x2 >,
		                 < 0x2 &adc 0x3 >,
		                 < 0x3 &adc 0x4 >,
		                 < 0x4 &adc 0x5 >,
		                 < 0x5 &adc 0x6 >; /* in zephyr\boards\nordic\nrf9160dk\nrf9160dk_nrf9160_common.dtsi:145 */
	};

	/* node '/reserved-memory' defined in zephyr\dts\vendor\nordic\nrf91xx_partition.dtsi:107 */
	reserved-memory {
		#address-cells = < 0x1 >; /* in zephyr\dts\vendor\nordic\nrf91xx_partition.dtsi:108 */
		#size-cells = < 0x1 >;    /* in zephyr\dts\vendor\nordic\nrf91xx_partition.dtsi:109 */
		ranges;                   /* in zephyr\dts\vendor\nordic\nrf91xx_partition.dtsi:110 */

		/* node '/reserved-memory/image_s@20000000' defined in zephyr\dts\vendor\nordic\nrf91xx_partition.dtsi:112 */
		sram0_s: image_s@20000000 {
			reg = < 0x20000000 0x16000 >; /* in zephyr\dts\vendor\nordic\nrf91xx_partition.dtsi:114 */
		};

		/* node '/reserved-memory/image_ns@20016000' defined in zephyr\dts\vendor\nordic\nrf91xx_partition.dtsi:117 */
		sram0_ns: image_ns@20016000 {
			reg = < 0x20016000 0x2a000 >; /* in zephyr\dts\vendor\nordic\nrf91xx_partition.dtsi:119 */
		};

		/* node '/reserved-memory/image_ns_modem@20016000' defined in zephyr\dts\vendor\nordic\nrf91xx_partition.dtsi:122 */
		sram0_ns_modem: image_ns_modem@20016000 {
			reg = < 0x20016000 0xa000 >; /* in zephyr\dts\vendor\nordic\nrf91xx_partition.dtsi:124 */
		};

		/* node '/reserved-memory/image_ns_app@20020000' defined in zephyr\dts\vendor\nordic\nrf91xx_partition.dtsi:127 */
		sram0_ns_app: image_ns_app@20020000 {
			reg = < 0x20020000 0x20000 >; /* in zephyr\dts\vendor\nordic\nrf91xx_partition.dtsi:129 */
		};
	};

	/* node '/status_leds' defined in ..\firmware_dev\app.overlay:44 */
	status_leds {
		compatible = "gpio-leds"; /* in ..\firmware_dev\app.overlay:45 */

		/* node '/status_leds/led_status_green' defined in ..\firmware_dev\app.overlay:46 */
		led_status_green: led_status_green {
			gpios = < &gpio0 0x8 0x0 >; /* in ..\firmware_dev\app.overlay:47 */
			label = "status green";     /* in ..\firmware_dev\app.overlay:48 */
		};

		/* node '/status_leds/led_status_red' defined in ..\firmware_dev\app.overlay:50 */
		led_status_red: led_status_red {
			gpios = < &gpio0 0x9 0x0 >; /* in ..\firmware_dev\app.overlay:51 */
			label = "status red";       /* in ..\firmware_dev\app.overlay:52 */
		};

		/* node '/status_leds/led_status_yellow' defined in ..\firmware_dev\app.overlay:54 */
		led_status_yellow: led_status_yellow {
			gpios = < &gpio0 0xa 0x0 >; /* in ..\firmware_dev\app.overlay:55 */
			label = "status yellow";    /* in ..\firmware_dev\app.overlay:56 */
		};
	};
};
